# RSL15 register map
Vendor: ONSemiconductor; Series: RSL15 Series; File version: 1.0
CPU: CM33 r0p4, little endian, MPU, FPU, 3 interrupt priority bits
Registers are 32-bit, read-write, reset 0x0 unless marked. A register's access mark holds for its fields unless they carry their own. Offsets are from the block's base; [hi:lo] are bit positions; {n}, {i} and the like mark numbered series.

## PCM — PCM Interface
Base 0x40001000
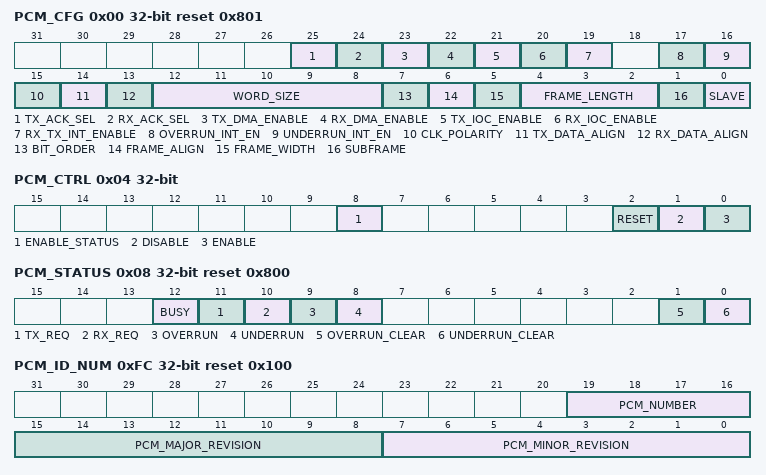
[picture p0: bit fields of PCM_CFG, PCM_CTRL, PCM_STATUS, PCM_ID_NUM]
0x00 PCM_CFG reset 0x801 — PCM Configuration Register
  [25] TX_ACK_SEL — Select which TX word acknowleges the TX request
    0=PCM_TX_ACK_DATA0 (TX data0 acknowledges the TX request); 1=PCM_TX_ACK_DATA1 (TX data1 acknowledges the TX request)
  [24] RX_ACK_SEL — Select which RX word acknowleges the RX request
    0=PCM_RX_ACK_DATA0 (RX data0 acknowledges the RX request); 1=PCM_RX_ACK_DATA1 (RX data1 acknowledges the RX request)
  [23] TX_DMA_ENABLE — Enable/disable the TX DMA request
    0=PCM_TX_DMA_DISABLE (No TX DMA request is generated); 1=PCM_TX_DMA_ENABLE (A TX DMA request is generated when new data is requested by the PCM interface)
  [22] RX_DMA_ENABLE — Enable/disable the RX DMA request
    0=PCM_RX_DMA_DISABLE (No RX DMA request is generated); 1=PCM_RX_DMA_ENABLE (An RX DMA request is generated when new data is received by the PCM interface)
  [21] TX_IOC_ENABLE — Enable/disable the TX IOC request
    0=PCM_TX_IOC_DISABLE (No TX IOC request is generated); 1=PCM_TX_IOC_ENABLE (A TX IOC request is generated when new data is requested by the PCM interface)
  [20] RX_IOC_ENABLE — Enable/disable the RX IOC request
    0=PCM_RX_IOC_DISABLE (No RX IOC request is generated); 1=PCM_RX_IOC_ENABLE (An RX IOC request is generated when new data is received by the PCM interface)
  [19] RX_TX_INT_ENABLE — Enable/disable the RX_TX interrupt
    0=PCM_RX_TX_INT_DISABLE (No RX_TX interrupt is raised); 1=PCM_RX_TX_INT_ENABLE (An RX_TX interrupt is raised when new data is received or requested by the PCM interface)
  [17] OVERRUN_INT_EN — Enable/disable the overrun interrupt
    0=PCM_OVERRUN_INT_DISABLE (No ERROR interrupt is raised when an overrun is detected); 1=PCM_OVERRUN_INT_ENABLE (An ERROR interrupt is raised when an overrun occurs on the PCM interface)
  [16] UNDERRUN_INT_EN — Enable/disable the underrun interrupt
    0=PCM_UNDERRUN_INT_DISABLE (No ERROR interrupt is raised when an underrun is detected); 1=PCM_UNDERRUN_INT_ENABLE (An ERROR interrupt is raised when an underrun occurs on the PCM interface)
  [15] CLK_POLARITY — Select the PCM clock polarity
    0=PCM_SAMPLE_FALLING_EDGE (PCM input data sampled on PCM_CLK falling edge); 1=PCM_SAMPLE_RISING_EDGE (PCM input data sampled on PCM_CLK rising edge)
  [14] TX_DATA_ALIGN — Select the TX data alignment
    0=PCM_TX_DATA_ALIGN_MSB (TX data is aligned on the MSB of the 32-bit TX buffer); 1=PCM_TX_DATA_ALIGN_LSB (TX data is aligned on the LSB of the 32-bit TX buffer)
  [13] RX_DATA_ALIGN — Select the RX data alignment
    0=PCM_RX_DATA_ALIGN_MSB (RX data is aligned on the MSB of the 32-bit RX buffer); 1=PCM_RX_DATA_ALIGN_LSB (RX data is aligned on the LSB of the 32-bit RX buffer)
  [12:8] WORD_SIZE — Select the number of bits per PCM word
    {v}=PCM_WORD_SIZE_{v+8} (Use {v+8}-bit words) (v=0..24)
  [7] BIT_ORDER — Select whether the data is transmitted starting with the MSB or LSB
    0=PCM_BIT_ORDER_MSB_FIRST (PCM data is ordered from MSB to LSB.); 1=PCM_BIT_ORDER_LSB_FIRST (PCM data is ordered from LSB to MSB.)
  [6] FRAME_ALIGN — Align the PCM frame signal to the first/last bit
    0=PCM_FRAME_ALIGN_LAST (Align the PCM frame signal to the last bit of the frame.); 1=PCM_FRAME_ALIGN_FIRST (Align the PCM frame signal to the first bit of the frame.)
  [5] FRAME_WIDTH — Use a long/short PCM frame signal
    0=PCM_FRAME_WIDTH_SHORT (The frame is high for one PCM clock period.); 1=PCM_FRAME_WIDTH_LONG (The frame is high for half of the frame length.)
  [4:2] FRAME_LENGTH — Select the number of words per PCM frame
    0=PCM_MULTIWORD_2 (A frame contains 2 words.); 1=PCM_MULTIWORD_4 (A frame contains 4 words.); 2=PCM_MULTIWORD_6 (A frame contains 6 words.); 3=PCM_MULTIWORD_8 (A frame contains 8 words.); 4=PCM_MULTIWORD_10 (A frame contains 10 words.); 5=PCM_MULTIWORD_12 (A frame contains 12 words.); 6=PCM_MULTIWORD_14 (A frame contains 14 words.); 7=PCM_MULTIWORD_16 (A frame contains 16 words.)
  [1] SUBFRAME — Enable the frame duration for each word
    0=PCM_SUBFRAME_DISABLE (Generate a frame signal every frame.); 1=PCM_SUBFRAME_ENABLE (Generate a frame signal every word.)
  [0] SLAVE — Use the PCM interface as a master/slave
    0=PCM_SELECT_MASTER (The PCM interface generates the PCM_FRAME.); 1=PCM_SELECT_SLAVE (The PCM interface received an external PCM_FRAME.)
0x04 PCM_CTRL (reset mask 0x100) — PCM Control Register
  [8] ENABLE_STATUS ro — PCM enable status
    0=PCM_STATUS_DISABLED (PCM interface is disabled); 1=PCM_STATUS_ENABLED (PCM interface is enabled)
  [2] RESET wo — Reset the PCM interface
    1=PCM_RESET (Reset the PCM interface)
  [1] DISABLE wo — Disable the PCM interface
    1=PCM_DISABLE (Disable the PCM interface)
  [0] ENABLE wo — Enable the PCM interface
    1=PCM_ENABLE (Enable the PCM interface)
0x08 PCM_STATUS reset 0x800 (reset mask 0x1F00)
  [12] BUSY ro — Indicate that the reception or transmission of the data is ongoing
    0=PCM_IDLE; 1=PCM_BUSY
  [11] TX_REQ ro — Indicate that TX data can be written
    0=PCM_TX_NO_REQ (PCM TX data has already been written); 1=PCM_TX_REQ (PCM TX data can be written)
  [10] RX_REQ ro — Indicate that RX data can be read
    0=PCM_RX_NO_REQ (No new PCM RX data available); 1=PCM_RX_REQ (New PCM RX data available)
  [9] OVERRUN ro — Indicate that an overrun occurred when receiving data
    0=PCM_OVERRUN_FALSE (No PCM input overrun detected); 1=PCM_OVERRUN_TRUE (PCM input overrun detected)
  [8] UNDERRUN ro — Indicate that an underrun occurred when transmitting data
    0=PCM_UNDERRUN_FALSE (No PCM output underrun detected); 1=PCM_UNDERRUN_TRUE (PCM output underrun detected)
  [1] OVERRUN_CLEAR wo — Clear the overrun status flag
    1=PCM_OVERRUN_CLEAR (Clear the PCM overrun bit)
  [0] UNDERRUN_CLEAR wo — Clear the underrun status flag
    1=PCM_UNDERRUN_CLEAR (Clear the PCM underrun bit)
0x10 PCM_TX_DATA0 — PCM Transmit Data 0 Register
  [31:0] TX_DATA0 — Data to transmit on channel 0
0x14 PCM_TX_DATA1 — PCM Transmit Data 1 Register
  [31:0] TX_DATA1 — Data to transmit on channel 1
0x18 PCM_RX_DATA0 ro — PCM Receive Data 0 Register
  [31:0] RX_DATA0 — Data received on channel 0
0x1C PCM_RX_DATA1 ro — PCM Receive Data 1 Register
  [31:0] RX_DATA1 — Data received on channel 1
0xFC PCM_ID_NUM ro reset 0x100 — PCM ID number
  [19:16] PCM_NUMBER — PCM Instance number
  [15:8] PCM_MAJOR_REVISION — PCM Major Revision number
    1=PCM_MAJOR_REVISION (PCM revision 1.0)
  [7:0] PCM_MINOR_REVISION — PCM Minor Revision number
    0=PCM_MINOR_REVISION (PCM revision 1.0)
